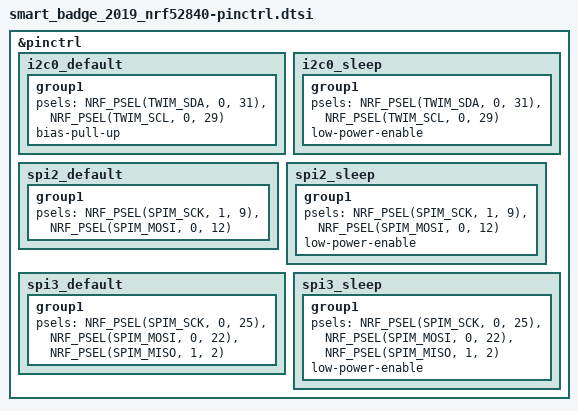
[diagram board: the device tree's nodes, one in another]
/*
 * Copyright (c) 2025 TE Connectivity
 * SPDX-License-Identifier: Apache-2.0
 */

&pinctrl {
	i2c0_default: i2c0_default {
		group1 {
			psels = <NRF_PSEL(TWIM_SDA, 0, 31)>,
				<NRF_PSEL(TWIM_SCL, 0, 29)>;
			bias-pull-up;
		};
	};

	i2c0_sleep: i2c0_sleep {
		group1 {
			psels = <NRF_PSEL(TWIM_SDA, 0, 31)>,
				<NRF_PSEL(TWIM_SCL, 0, 29)>;
			low-power-enable;
		};
	};

	/* SPI2: E-ink display (SDI=P0.12, SCLK=P1.09) */
	spi2_default: spi2_default {
		group1 {
			psels = <NRF_PSEL(SPIM_SCK, 1, 9)>,
				<NRF_PSEL(SPIM_MOSI, 0, 12)>;
		};
	};

	spi2_sleep: spi2_sleep {
		group1 {
			psels = <NRF_PSEL(SPIM_SCK, 1, 9)>,
				<NRF_PSEL(SPIM_MOSI, 0, 12)>;
			low-power-enable;
		};
	};

	/* SPI3: External flash MX25R6435F (QSPI pins used as SPI) */
	spi3_default: spi3_default {
		group1 {
			psels = <NRF_PSEL(SPIM_SCK, 0, 25)>,
				<NRF_PSEL(SPIM_MOSI, 0, 22)>,
				<NRF_PSEL(SPIM_MISO, 1, 2)>;
		};
	};

	spi3_sleep: spi3_sleep {
		group1 {
			psels = <NRF_PSEL(SPIM_SCK, 0, 25)>,
				<NRF_PSEL(SPIM_MOSI, 0, 22)>,
				<NRF_PSEL(SPIM_MISO, 1, 2)>;
			low-power-enable;
		};
	};
};
